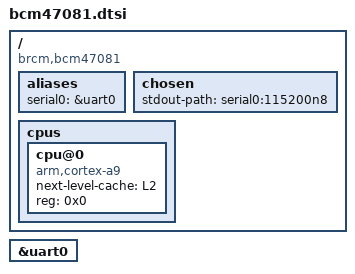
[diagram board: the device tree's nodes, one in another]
#include "bcm5301x.dtsi"
/ {
	compatible = "brcm,bcm47081";
	aliases {
		serial0 = &uart0;
	};
	chosen {
		stdout-path = "serial0:115200n8";
	};
	cpus {
		#address-cells = <1>;
		#size-cells = <0>;
		cpu@0 {
			device_type = "cpu";
			compatible = "arm,cortex-a9";
			next-level-cache = <&L2>;
			reg = <0x0>;
		};
	};
};
&uart0 {
	status = "okay";
};
